VERSION ""

NS_ :

BS_:

BU_: AfterTreatment_1 Transmission_2 Engine_2 Accelerator
VAL_TABLE_ SCR_Thermal_Mgmt_Active 3 "Don't care" 2 "Reserved" 1 "SCR Thermal Mgmt is active

" 0 "SCR Thermal Mgmt is not active

" ;
VAL_TABLE_ DPF_Thermal_Mgmt_Active 3 "Don't care" 2 "Reserved" 1 "DPF Thermal Mgmtis active" 0 "DPF Thermal Mgmt is not active" ;
VAL_TABLE_ Momentary_Eng_Max_Pwr_En_Feedbk 3 "don't care" 2 "reserved" 1 "supported" 0 "disabled" ;
VAL_TABLE_ Veh_Accel_Rate_Limit_Status 3 "Not available" 2 "Reserved" 1 "Limit active" 0 "Limit not active" ;
VAL_TABLE_ Accel_2_Low_Idle_Switch 3 "Not available" 2 "Error" 1 "Accel pedal 2 in low idle" 0 "Accel pedal 2 not in low idle " ;
VAL_TABLE_ Road_Speed_Limit_Status 3 "Not available" 2 "Error

" 1 "Not Active

" 0 "Active

" ;
VAL_TABLE_ Accel_Pedal_Kickdown_Switch 3 "Not available" 2 "Error

" 1 "Kickdown active

" 0 "Kickdown passive

" ;
VAL_TABLE_ Accel_1_Low_Idle_Switch 3 "Not available" 2 "Error" 1 "Accel pedal 1 in low idle" 0 "Accel pedal 1 not in low idle " ;

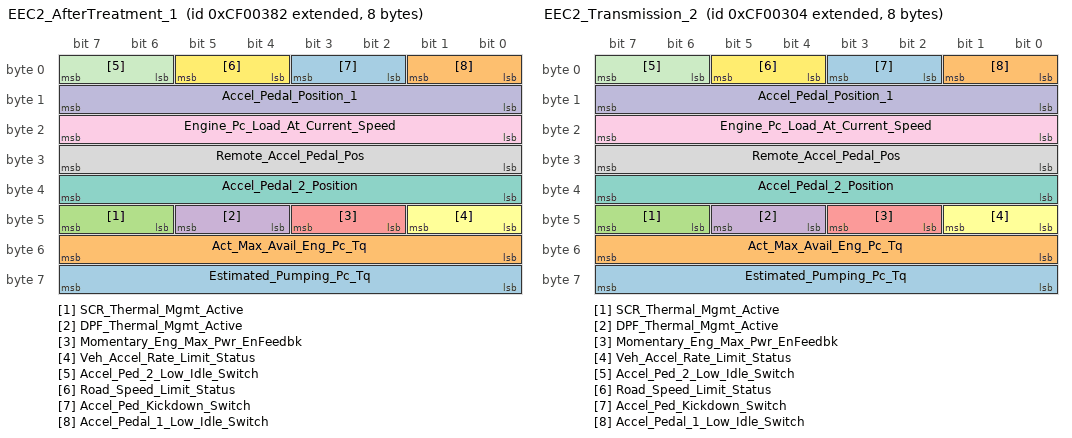
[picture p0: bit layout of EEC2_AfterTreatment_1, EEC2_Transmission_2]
BO_ 2364539778 EEC2_AfterTreatment_1: 8 Accelerator
 SG_ Estimated_Pumping_Pc_Tq : 56|8@1+ (1,-125) [-125|125] "%"  AfterTreatment_1
 SG_ Act_Max_Avail_Eng_Pc_Tq : 48|8@1+ (0.4,0) [0|100] "%"  AfterTreatment_1
 SG_ SCR_Thermal_Mgmt_Active : 46|2@1+ (1,0) [0|3] ""  AfterTreatment_1
 SG_ DPF_Thermal_Mgmt_Active : 44|2@1+ (1,0) [0|3] ""  AfterTreatment_1
 SG_ Momentary_Eng_Max_Pwr_EnFeedbk : 42|2@1+ (1,0) [0|3] ""  AfterTreatment_1
 SG_ Veh_Accel_Rate_Limit_Status : 40|2@1+ (1,0) [0|3] ""  AfterTreatment_1
 SG_ Accel_Pedal_2_Position : 32|8@1+ (0.4,0) [0|100] "%"  AfterTreatment_1
 SG_ Remote_Accel_Pedal_Pos : 24|8@1+ (0.4,0) [0|100] "%"  AfterTreatment_1
 SG_ Engine_Pc_Load_At_Current_Speed : 16|8@1+ (1,0) [0|250] "%"  AfterTreatment_1
 SG_ Accel_Pedal_Position_1 : 8|8@1+ (0.4,0) [0|100] "%"  AfterTreatment_1
 SG_ Accel_Ped_2_Low_Idle_Switch : 6|2@1+ (1,0) [0|3] ""  AfterTreatment_1
 SG_ Road_Speed_Limit_Status : 4|2@1+ (1,0) [0|3] ""  AfterTreatment_1
 SG_ Accel_Ped_Kickdown_Switch : 2|2@1+ (1,0) [0|3] ""  AfterTreatment_1
 SG_ Accel_Pedal_1_Low_Idle_Switch : 0|2@1+ (1,0) [0|3] ""  AfterTreatment_1

BO_ 2364539652 EEC2_Transmission_2: 8 Accelerator
 SG_ Estimated_Pumping_Pc_Tq : 56|8@1+ (1,-125) [-125|125] "%"  Transmission_2
 SG_ Act_Max_Avail_Eng_Pc_Tq : 48|8@1+ (0.4,0) [0|100] "%"  Transmission_2
 SG_ SCR_Thermal_Mgmt_Active : 46|2@1+ (1,0) [0|3] ""  Transmission_2
 SG_ DPF_Thermal_Mgmt_Active : 44|2@1+ (1,0) [0|3] ""  Transmission_2
 SG_ Momentary_Eng_Max_Pwr_EnFeedbk : 42|2@1+ (1,0) [0|3] ""  Transmission_2
 SG_ Veh_Accel_Rate_Limit_Status : 40|2@1+ (1,0) [0|3] ""  Transmission_2
 SG_ Accel_Pedal_2_Position : 32|8@1+ (0.4,0) [0|100] "%"  Transmission_2
 SG_ Remote_Accel_Pedal_Pos : 24|8@1+ (0.4,0) [0|100] "%"  Transmission_2
 SG_ Engine_Pc_Load_At_Current_Speed : 16|8@1+ (1,0) [0|250] "%"  Transmission_2
 SG_ Accel_Pedal_Position_1 : 8|8@1+ (0.4,0) [0|100] "%"  Transmission_2
 SG_ Accel_Ped_2_Low_Idle_Switch : 6|2@1+ (1,0) [0|3] ""  Transmission_2
 SG_ Road_Speed_Limit_Status : 4|2@1+ (1,0) [0|3] ""  Transmission_2
 SG_ Accel_Ped_Kickdown_Switch : 2|2@1+ (1,0) [0|3] ""  Transmission_2
 SG_ Accel_Pedal_1_Low_Idle_Switch : 0|2@1+ (1,0) [0|3] ""  Transmission_2

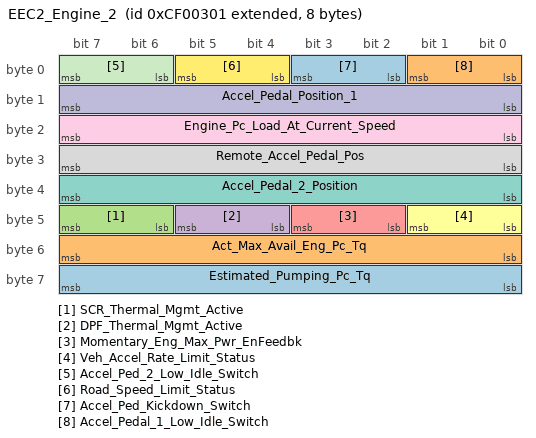
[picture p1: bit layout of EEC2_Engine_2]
BO_ 2364539649 EEC2_Engine_2: 8 Accelerator
 SG_ Estimated_Pumping_Pc_Tq : 56|8@1+ (1,-125) [-125|125] "%"  Engine_2
 SG_ Act_Max_Avail_Eng_Pc_Tq : 48|8@1+ (0.4,0) [0|100] "%"  Engine_2
 SG_ SCR_Thermal_Mgmt_Active : 46|2@1+ (1,0) [0|3] ""  Engine_2
 SG_ DPF_Thermal_Mgmt_Active : 44|2@1+ (1,0) [0|3] ""  Engine_2
 SG_ Momentary_Eng_Max_Pwr_EnFeedbk : 42|2@1+ (1,0) [0|3] ""  Engine_2
 SG_ Veh_Accel_Rate_Limit_Status : 40|2@1+ (1,0) [0|3] ""  Engine_2
 SG_ Accel_Pedal_2_Position : 32|8@1+ (0.4,0) [0|100] "%"  Engine_2
 SG_ Remote_Accel_Pedal_Pos : 24|8@1+ (0.4,0) [0|100] "%"  Engine_2
 SG_ Engine_Pc_Load_At_Current_Speed : 16|8@1+ (1,0) [0|250] "%"  Engine_2
 SG_ Accel_Pedal_Position_1 : 8|8@1+ (0.4,0) [0|100] "%"  Engine_2
 SG_ Accel_Ped_2_Low_Idle_Switch : 6|2@1+ (1,0) [0|3] ""  Engine_2
 SG_ Road_Speed_Limit_Status : 4|2@1+ (1,0) [0|3] ""  Engine_2
 SG_ Accel_Ped_Kickdown_Switch : 2|2@1+ (1,0) [0|3] ""  Engine_2
 SG_ Accel_Pedal_1_Low_Idle_Switch : 0|2@1+ (1,0) [0|3] ""  Engine_2

BA_DEF_  "BusType" STRING ;
BA_DEF_DEF_  "BusType" "CAN";
VAL_ 2364539778 SCR_Thermal_Mgmt_Active 3 "Don't care" 2 "Reserved" 1 "SCR Thermal Mgmt is active

" 0 "SCR Thermal Mgmt is not active

" ;
VAL_ 2364539778 DPF_Thermal_Mgmt_Active 3 "Don't care" 2 "Reserved" 1 "DPF Thermal Mgmtis active" 0 "DPF Thermal Mgmt is not active" ;
VAL_ 2364539778 Momentary_Eng_Max_Pwr_EnFeedbk 3 "don't care" 2 "reserved" 1 "supported" 0 "disabled" ;
VAL_ 2364539778 Veh_Accel_Rate_Limit_Status 3 "Not available" 2 "Reserved" 1 "Limit active" 0 "Limit not active" ;
VAL_ 2364539778 Accel_Ped_2_Low_Idle_Switch 3 "Not available" 2 "Error" 1 "Accel pedal 2 in low idle" 0 "Accel pedal 2 not in low idle " ;
VAL_ 2364539778 Road_Speed_Limit_Status 3 "Not available" 2 "Error

" 1 "Not Active

" 0 "Active

" ;
VAL_ 2364539778 Accel_Ped_Kickdown_Switch 3 "Not available" 2 "Error

" 1 "Kickdown active

" 0 "Kickdown passive

" ;
VAL_ 2364539778 Accel_Pedal_1_Low_Idle_Switch 3 "Not available" 2 "Error" 1 "Accel pedal 1 in low idle" 0 "Accel pedal 1 not in low idle " ;
VAL_ 2364539652 SCR_Thermal_Mgmt_Active 3 "Don't care" 2 "Reserved" 1 "SCR Thermal Mgmt is active

" 0 "SCR Thermal Mgmt is not active

" ;
VAL_ 2364539652 DPF_Thermal_Mgmt_Active 3 "Don't care" 2 "Reserved" 1 "DPF Thermal Mgmtis active" 0 "DPF Thermal Mgmt is not active" ;
VAL_ 2364539652 Momentary_Eng_Max_Pwr_EnFeedbk 3 "don't care" 2 "reserved" 1 "supported" 0 "disabled" ;
VAL_ 2364539652 Veh_Accel_Rate_Limit_Status 3 "Not available" 2 "Reserved" 1 "Limit active" 0 "Limit not active" ;
VAL_ 2364539652 Accel_Ped_2_Low_Idle_Switch 3 "Not available" 2 "Error" 1 "Accel pedal 2 in low idle" 0 "Accel pedal 2 not in low idle " ;
VAL_ 2364539652 Road_Speed_Limit_Status 3 "Not available" 2 "Error

" 1 "Not Active

" 0 "Active

" ;
VAL_ 2364539652 Accel_Ped_Kickdown_Switch 3 "Not available" 2 "Error

" 1 "Kickdown active

" 0 "Kickdown passive

" ;
VAL_ 2364539652 Accel_Pedal_1_Low_Idle_Switch 3 "Not available" 2 "Error" 1 "Accel pedal 1 in low idle" 0 "Accel pedal 1 not in low idle " ;
VAL_ 2364539649 SCR_Thermal_Mgmt_Active 3 "Don't care" 2 "Reserved" 1 "SCR Thermal Mgmt is active

" 0 "SCR Thermal Mgmt is not active

" ;
VAL_ 2364539649 DPF_Thermal_Mgmt_Active 3 "Don't care" 2 "Reserved" 1 "DPF Thermal Mgmtis active" 0 "DPF Thermal Mgmt is not active" ;
VAL_ 2364539649 Momentary_Eng_Max_Pwr_EnFeedbk 3 "don't care" 2 "reserved" 1 "supported" 0 "disabled" ;
VAL_ 2364539649 Veh_Accel_Rate_Limit_Status 3 "Not available" 2 "Reserved" 1 "Limit active" 0 "Limit not active" ;
VAL_ 2364539649 Accel_Ped_2_Low_Idle_Switch 3 "Not available" 2 "Error" 1 "Accel pedal 2 in low idle" 0 "Accel pedal 2 not in low idle " ;
VAL_ 2364539649 Road_Speed_Limit_Status 3 "Not available" 2 "Error

" 1 "Not Active

" 0 "Active

" ;
VAL_ 2364539649 Accel_Ped_Kickdown_Switch 3 "Not available" 2 "Error

" 1 "Kickdown active

" 0 "Kickdown passive

" ;
VAL_ 2364539649 Accel_Pedal_1_Low_Idle_Switch 3 "Not available" 2 "Error" 1 "Accel pedal 1 in low idle" 0 "Accel pedal 1 not in low idle " ;
